AUTOSAR XML (schema 00053)
package /SWA
  composition sw component type RootComposition
    component A: type=A
    component B: type=B
    connect A.PPort -> B.RPort
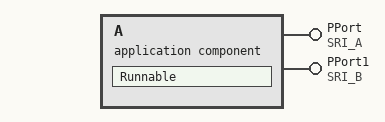
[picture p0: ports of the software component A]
  application sw component type A
    provide port PPort: provided-interface=SRI_A
    provide port PPort1: provided-interface=SRI_B
    behavior InternalBehavior
      runnable Runnable: symbol=A_Runnable
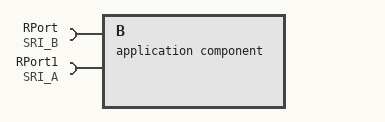
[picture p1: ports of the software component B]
  application sw component type B
    require port RPort: required-interface=SRI_B
    require port RPort1: required-interface=SRI_A
    behavior InternalBehavior
      data received event DataReceivedEvent
  sender receiver interface SRI_A
    data E1: type=ApplicationPrimitiveDataType
  sender receiver interface SRI_B
    data E1: type=ApplicationPrimitiveDataType
    data E2: type=ApplicationPrimitiveDataType
package /DataTypes
  app type ApplicationPrimitiveDataType: category=VALUE
